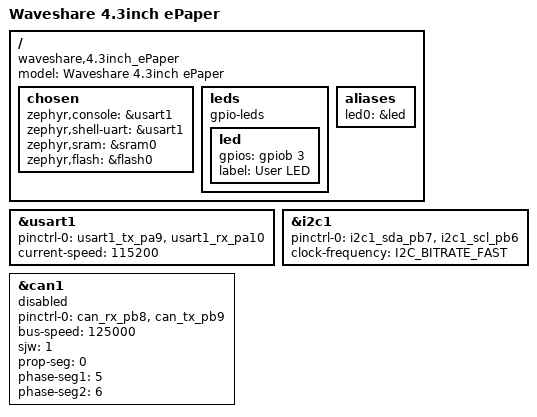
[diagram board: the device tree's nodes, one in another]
/*
 * Copyright (c) 2021 Maarten Zanders
 *
 * SPDX-License-Identifier: Apache-2.0
 */

/dts-v1/;
#include <st/f1/stm32f103Xe.dtsi>
#include <st/f1/stm32f103z(c-d-e)tx-pinctrl.dtsi>

/ {
	model = "Waveshare 4.3inch ePaper";
	compatible = "waveshare,4.3inch_ePaper";

	chosen {
		zephyr,console = &usart1;
		zephyr,shell-uart = &usart1;
		zephyr,sram = &sram0;
		zephyr,flash = &flash0;
	};

	leds {
		compatible = "gpio-leds";
		led: led {
			gpios = <&gpiob 3 GPIO_ACTIVE_HIGH>;
			label = "User LED";
		};
	};

	aliases {
		led0 = &led;
	};
};

&usart1 {
	pinctrl-0 = <&usart1_tx_pa9 &usart1_rx_pa10>;
	current-speed = <115200>;
	status = "okay";
};

&i2c1 {
	pinctrl-0 = <&i2c1_sda_pb7 &i2c1_scl_pb6>;
	status = "okay";
	clock-frequency = <I2C_BITRATE_FAST>;
};

&can1 {
	pinctrl-0 = <&can_rx_pb8 &can_tx_pb9>;
	/*
	 * make sure CAN and USB are not enabled at the same time
	 * because they share interrupts 19, 20 (stm32f103Xb.dtsi)
	 * reference: RM0008 rev20 page 205
	 */
	status = "disabled";
	bus-speed = <125000>;
	sjw = <1>;
	prop-seg = <0>;
	phase-seg1 = <5>;
	phase-seg2 = <6>;
};
